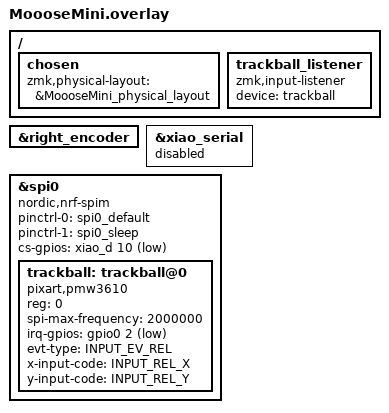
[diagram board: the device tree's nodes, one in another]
#include <zephyr/dt-bindings/input/input-event-codes.h>
#include "MoooseMini.dtsi"

/ {
    chosen {
        zmk,physical-layout = &MoooseMini_physical_layout;
    };

    trackball_listener: trackball_listener {
        compatible = "zmk,input-listener";
        device = <&trackball>;
    };
};

&right_encoder {
    status = "okay";
};

&xiao_serial {
    status = "disabled";
};

&spi0 {
    status = "okay";
    compatible = "nordic,nrf-spim";
    pinctrl-0 = <&spi0_default>;
    pinctrl-1 = <&spi0_sleep>;
    pinctrl-names = "default", "sleep";
    cs-gpios = <&xiao_d 10 GPIO_ACTIVE_LOW>;

    trackball: trackball@0 {
        status = "okay";
        compatible = "pixart,pmw3610";
        reg = <0>;
        spi-max-frequency = <2000000>;
        irq-gpios = <&gpio0 2 (GPIO_ACTIVE_LOW | GPIO_PULL_UP)>;
        evt-type = <INPUT_EV_REL>;
        x-input-code = <INPUT_REL_X>;
        y-input-code = <INPUT_REL_Y>;
        // disable force-awake
        // force-awake;
        // disable-burst-read;
    };
};
